VERSION ""

NS_ :

BS_:

BU_:
    NEO
    MCU
    GTW
    EPAS
    DI
    ESP
    SBW
    STW
	APP
	DAS

BO_ 513 SDM1: 5 GTW
 SG_ SDM_bcklPassStatus : 3|2@0+ (1,0) [0|3] "" NEO
 SG_ SDM_bcklDrivStatus : 5|2@0+ (1,0) [0|3] "" NEO

BO_ 643 BODY_R1: 8 GTW
 SG_ AirTemp_Insd : 47|8@0+ (0.25,0) [0|63.5] "C"  NEO
 SG_ AirTemp_Outsd : 63|8@0+ (0.5,-40) [-40|86.5] "C"  NEO
 SG_ Bckl_Sw_RL_Stat_SAM_R : 49|2@0+ (1,0) [-1|4] ""  NEO
 SG_ Bckl_Sw_RM_Stat_SAM_R : 53|2@0+ (1,0) [-1|4] ""  NEO
 SG_ Bckl_Sw_RR_Stat_SAM_R : 51|2@0+ (1,0) [-1|4] ""  NEO
 SG_ DL_RLtch_Stat : 9|2@0+ (1,0) [-1|4] ""  NEO
 SG_ DrRLtch_FL_Stat : 1|2@0+ (1,0) [-1|4] ""  NEO
 SG_ DrRLtch_FR_Stat : 3|2@0+ (1,0) [-1|4] ""  NEO
 SG_ DrRLtch_RL_Stat : 5|2@0+ (1,0) [-1|4] ""  NEO
 SG_ DrRLtch_RR_Stat : 7|2@0+ (1,0) [-1|4] ""  NEO
 SG_ EngHd_Stat : 11|2@0+ (1,0) [-1|4] ""  NEO
 SG_ LoBm_On_Rq : 32|1@0+ (1,0) [0|1] ""  NEO
 SG_ HiBm_On : 33|1@0+ (1,0) [0|1] ""  NEO
 SG_ Hrn_On : 26|1@0+ (1,0) [0|1] ""  NEO
 SG_ IrLmp_D_Lt_Flt : 34|1@0+ (1,0) [0|1] ""  NEO
 SG_ IrLmp_P_Rt_Flt : 35|1@0+ (1,0) [0|1] ""  NEO
 SG_ LgtSens_Twlgt : 18|3@0+ (1,0) [0|7] "Steps"  NEO
 SG_ LgtSens_SNA : 19|1@0+ (1,0) [0|1] ""  NEO
 SG_ LgtSens_Tunnel : 20|1@0+ (1,0) [0|1] ""  NEO
 SG_ LgtSens_Flt : 21|1@0+ (1,0) [0|1] ""  NEO
 SG_ LgtSens_Night : 22|1@0+ (1,0) [-1|2] ""  NEO
 SG_ ADL_LoBm_On_Rq : 23|1@0+ (1,0) [0|1] ""  NEO
 SG_ LoBm_D_Lt_Flt : 36|1@0+ (1,0) [0|1] ""  NEO
 SG_ LoBm_P_Rt_Flt : 37|1@0+ (1,0) [0|1] ""  NEO
 SG_ MPkBrk_Stat : 28|1@0+ (1,0) [-1|2] ""  NEO
 SG_ RevGr_Engg : 39|2@0+ (1,0) [-1|4] ""  NEO
 SG_ StW_Cond_Stat : 55|2@0+ (1,0) [-1|4] ""  NEO
 SG_ Term54_Actv : 27|1@0+ (1,0) [0|1] ""  NEO
 SG_ Trlr_Stat : 25|2@0+ (1,0) [-1|4] ""  NEO
 SG_ VTA_Alm_Actv : 13|1@0+ (1,0) [0|1] ""  NEO
 SG_ WprOutsdPkPosn : 29|1@0+ (1,0) [0|1] ""  NEO

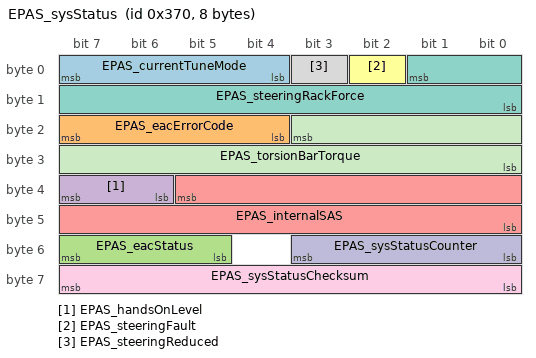
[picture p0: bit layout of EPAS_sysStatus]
BO_ 880 EPAS_sysStatus: 8 EPAS
 SG_ EPAS_currentTuneMode : 7|4@0+ (1,0) [8|15] ""  NEO
 SG_ EPAS_eacErrorCode : 23|4@0+ (1,0) [-1|16] ""  NEO
 SG_ EPAS_eacStatus : 55|3@0+ (1,0) [5|7] ""  NEO
 SG_ EPAS_handsOnLevel : 39|2@0+ (1,0) [-1|4] ""  NEO
 SG_ EPAS_internalSAS : 37|14@0+ (0.1,-819.200012) [0|0] "deg"  NEO
 SG_ EPAS_steeringFault : 2|1@0+ (1,0) [-1|2] ""  NEO
 SG_ EPAS_steeringRackForce : 1|10@0+ (50,-25575) [0|0] "N" NEO
 SG_ EPAS_steeringReduced : 3|1@0+ (1,0) [-1|2] ""  NEO
 SG_ EPAS_sysStatusChecksum : 63|8@0+ (1,0) [0|255] ""  NEO
 SG_ EPAS_sysStatusCounter : 51|4@0+ (1,0) [0|15] ""  NEO
 SG_ EPAS_torsionBarTorque : 19|12@0+ (0.01,-20.5) [0|0] "Nm"  NEO

VAL_ 643 AirTemp_Insd 255 "SNA" ;
VAL_ 643 AirTemp_Outsd 254 "INIT" 255 "SNA" ;
VAL_ 643 Bckl_Sw_RL_Stat_SAM_R 2 "FLT" 1 "NOT" 0 "OK" 3 "SNA" ;
VAL_ 643 Bckl_Sw_RM_Stat_SAM_R 2 "FLT" 1 "NOT" 0 "OK" 3 "SNA" ;
VAL_ 643 Bckl_Sw_RR_Stat_SAM_R 2 "FLT" 1 "NOT" 0 "OK" 3 "SNA" ;
VAL_ 643 DL_RLtch_Stat 1 "CLS" 0 "NDEF0" 2 "OPN" 3 "SNA" ;
VAL_ 643 DrRLtch_FL_Stat 1 "CLS" 0 "NDEF0" 2 "OPN" 3 "SNA" ;
VAL_ 643 DrRLtch_FR_Stat 1 "CLS" 0 "NDEF0" 2 "OPN" 3 "SNA" ;
VAL_ 643 DrRLtch_RL_Stat 1 "CLS" 0 "NDEF0" 2 "OPN" 3 "SNA" ;
VAL_ 643 DrRLtch_RR_Stat 1 "CLS" 0 "NDEF0" 2 "OPN" 3 "SNA" ;
VAL_ 643 EngHd_Stat 1 "CLS" 0 "NDEF0" 2 "OPN" 3 "SNA" ;
VAL_ 643 LgtSens_Night 0 "DAY" 1 "NIGHT" ;
VAL_ 643 MPkBrk_Stat 1 "ENGG" 0 "RELS" ;
VAL_ 643 RevGr_Engg 0 "DISENGG" 1 "ENGG" 2 "NDEF2" 3 "SNA" ;
VAL_ 643 StW_Cond_Stat 3 "BLINK" 1 "NDEF1" 0 "OFF" 2 "ON" ;
VAL_ 643 Trlr_Stat 2 "NDEF2" 0 "NONE" 1 "OK" 3 "SNA" ;
VAL_ 880 EPAS_currentTuneMode 1 "DM_COMFORT" 3 "DM_SPORT" 2 "DM_STANDARD" 0 "FAIL_SAFE_DEFAULT" 4 "RWD_COMFORT" 6 "RWD_SPORT" 5 "RWD_STANDARD" 7 "UNAVAILABLE" ;
VAL_ 880 EPAS_eacErrorCode 14 "EAC_ERROR_EPB_INHIBIT" 3 "EAC_ERROR_HANDS_ON" 7 "EAC_ERROR_HIGH_ANGLE_RATE_REQ" 9 "EAC_ERROR_HIGH_ANGLE_RATE_SAFETY" 6 "EAC_ERROR_HIGH_ANGLE_REQ" 8 "EAC_ERROR_HIGH_ANGLE_SAFETY" 10 "EAC_ERROR_HIGH_MMOT_SAFETY" 11 "EAC_ERROR_HIGH_TORSION_SAFETY" 0 "EAC_ERROR_IDLE" 12 "EAC_ERROR_LOW_ASSIST" 2 "EAC_ERROR_MAX_SPEED" 1 "EAC_ERROR_MIN_SPEED" 13 "EAC_ERROR_PINION_VEL_DIFF" 4 "EAC_ERROR_TMP_FAULT" 5 "EAR_ERROR_MAX_STEER_DELTA" 15 "SNA" ;
VAL_ 880 EPAS_eacStatus 2 "EAC_ACTIVE" 1 "EAC_AVAILABLE" 3 "EAC_FAULT" 0 "EAC_INHIBITED" 4 "SNA" ;
VAL_ 880 EPAS_handsOnLevel 0 "0" 1 "1" 2 "2" 3 "3" ;
VAL_ 880 EPAS_steeringFault 1 "FAULT" 0 "NO_FAULT" ;
VAL_ 880 EPAS_steeringRackForce 1022 "NOT_IN_SPEC" 1023 "SNA" ;
VAL_ 880 EPAS_steeringReduced 0 "NORMAL_ASSIST" 1 "REDUCED_ASSIST" ;
VAL_ 880 EPAS_torsionBarTorque 0 "SEE_SPECIFICATION" 4095 "SNA" 4094 "UNDEFINABLE_DATA" ;
